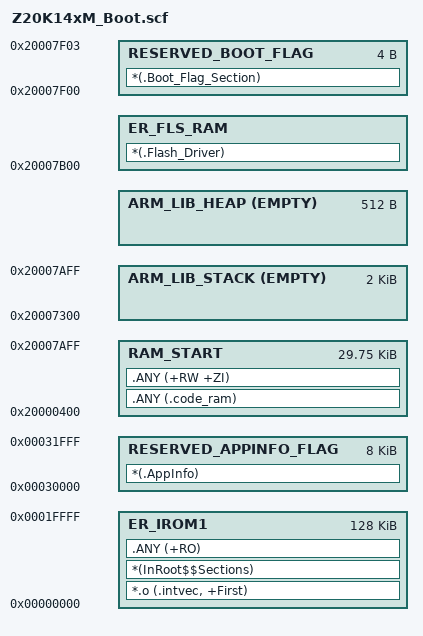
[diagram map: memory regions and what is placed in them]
#! armclang --target=arm-arm-none-eabi -mcpu=cortex-m4 -xc -E
; *************************************************************
; *** Scatter-Loading Description File                      ***
; *************************************************************

#define pflash_start               0x00000000
#define pflash_size                0x00020000   

#define dflash_start               0x01000000
#define dflash_size                0x00020000    

#define flash_ifr_start            0x02000000
#define flash_ifr_size             0x00008000    


#define ram_bl_start               0x20000400
#define ram_bl_size                (0x20007B00-0x20000400)    
#define ram_bl_end                 ram_bl_start + ram_bl_size


LR_IROM1 pflash_start pflash_size  {    ; load region size_region
  ER_IROM1 pflash_start pflash_size  {  ; load address = execution address
   *.o (.intvec, +First)
   *(InRoot$$Sections)
   .ANY (+RO)
  }
  
  RESERVED_BOOT_FLAG 0x20007F00 0x4 {
  *(.Boot_Flag_Section)
  }
  
    RESERVED_APPINFO_FLAG 0x00030000  0x2000 {
  *(.AppInfo)
  }
  

  
  RAM_START ram_bl_start ram_bl_size  {  
   .ANY (.code_ram)        ; code execution in ram
   .ANY (+RW +ZI)          ; RW data
  }
  
  ARM_LIB_STACK ram_bl_end EMPTY -0x800     {}; Stack region growing down
  ARM_LIB_HEAP	ImageBase(ARM_LIB_STACK) EMPTY -0x200	 {} ; heap region



}

RESERVED_FLASH_DRIVER 0x20007B00 0x400 {
  ER_FLS_RAM 0x20007B00  {*(.Flash_Driver)}
} 

